# DA14531 register map
Vendor: Dialog; Series: DA14531; File version: 1.2
CPU: CM0 r1p0, little endian, MPU, FPU, 3 interrupt priority bits
Registers are 16-bit, read-write, reset 0x0 unless marked. A register's access mark holds for its fields unless they carry their own. Offsets are from the block's base; [hi:lo] are bit positions; {n}, {i} and the like mark numbered series.

## PATCH — PATCH registers
Base 0x40080000
0x00 PATCH_VALID_REG 32-bit
  [21:0] PATCH_VALID
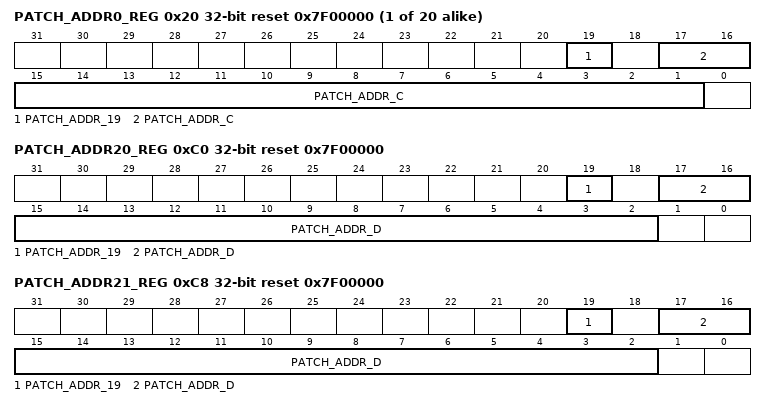
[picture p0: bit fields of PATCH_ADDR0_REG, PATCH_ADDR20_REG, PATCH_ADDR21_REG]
{0x20+8i} PATCH_ADDR{i}_REG 32-bit reset 0x7F00000 (i=0..19)
  [19] PATCH_ADDR_19, [17:1] PATCH_ADDR_C
0xC0 PATCH_ADDR20_REG 32-bit reset 0x7F00000
  [19] PATCH_ADDR_19, [17:2] PATCH_ADDR_D
0xC4 PATCH_DATA20_REG 32-bit (reset mask 0x7FFFFFFF)
  [31:0] PATCH_DATA
0xC8 PATCH_ADDR21_REG 32-bit reset 0x7F00000
  [19] PATCH_ADDR_19, [17:2] PATCH_ADDR_D
0xCC PATCH_DATA21_REG 32-bit (reset mask 0x7FFFFFFF)
  [31:0] PATCH_DATA

## QUADEC — QUADEC registers
Base 0x50000200
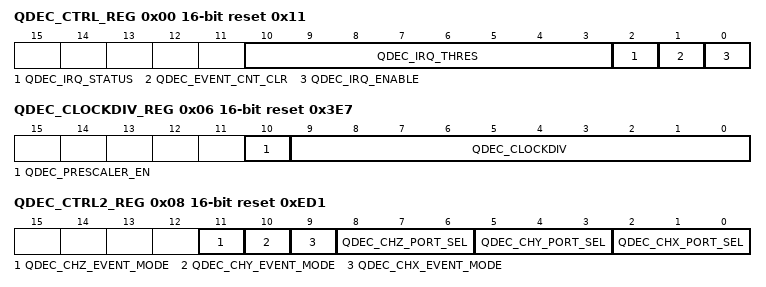
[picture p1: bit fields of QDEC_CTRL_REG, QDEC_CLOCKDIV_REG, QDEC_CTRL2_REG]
0x00 QDEC_CTRL_REG reset 0x11 — Quad Decoder control register
  [10:3] QDEC_IRQ_THRES — Defines the number of events on either counter (X or Y or Z) that need to be reached before an interrupt is generated. Events are equal to QDEC_IRQ_THRES+1.
  [2] QDEC_IRQ_STATUS — 1 = Interrupt is occured. 0 = No interrupt pending Write 1 will clear the pending interrupt
  [1] QDEC_EVENT_CNT_CLR — Writing 1 QDEC_EVENT_CNT_REG is cleared
  [0] QDEC_IRQ_ENABLE — 0 = interrupt is masked 1 = interrupt is enabled
0x02 QDEC_XCNT_REG — Counter value of the X Axis
  [15:0] QDEC_X_CNT ro — Contains a signed value of the events. Zero when channel is disabled
0x04 QDEC_YCNT_REG — Counter value of the Y Axis
  [15:0] QDEC_Y_CNT ro — Contains a signed value of the events. Zero when channel is disabled
0x06 QDEC_CLOCKDIV_REG reset 0x3E7 — Clock divider register
  [10] QDEC_PRESCALER_EN — 0 = no prescaler enabled 1 = in sleep and active mode, quadrature clock is divided by 2
  [9:0] QDEC_CLOCKDIV — Contains the number of the input clock cycles minus one, that are required to generate one logic clock cycle. Clock divider is bypassed when system runs at LP_CLK
0x08 QDEC_CTRL2_REG reset 0xED1 — Quad Decoder port selection register
  [11] QDEC_CHZ_EVENT_MODE — 0 = Normal quadrature counting 1 = Counts rising and falling edge of both ports (if both ports change at the same time, counter increases by 1)
  [10] QDEC_CHY_EVENT_MODE — 0 = Normal quadrature counting 1 = Counts rising and falling edge of both ports (if both ports change at the same time, counter increases by 1)
  [9] QDEC_CHX_EVENT_MODE — 0 = Normal quadrature counting 1 = Counts rising and falling edge of both ports (if both ports change at the same time, counter increases by 1)
  [8:6] QDEC_CHZ_PORT_SEL — Defines which GPIOs are mapped on Channel Z 0: none 1: P0[2] -> CHZ_A, P0[5] -> CHZ_B 2: P0[1] -> CHZ_A, P0[4] -> CHZ_B 3: P0[3] -> CHZ_A, P0[10] -> CHZ_B 4: P0[6] -> CHZ_A, P0[7] -> CHZ_B 5: P0[8] -> CHZ_A, P0[9] -> CHZ_B 6: P0[0] -> CHZ_A, P0[11] -> CHZ_B 7: none
  [5:3] QDEC_CHY_PORT_SEL — Defines which GPIOs are mapped on Channel Y 0: none 1: P0[2] -> CHY_A, P0[5] -> CHY_B 2: P0[1] -> CHY_A, P0[4] -> CHY_B 3: P0[3] -> CHY_A, P0[10] -> CHY_B 4: P0[6] -> CHY_A, P0[7] -> CHY_B 5: P0[8] -> CHY_A, P0[9] -> CHY_B 6: P0[0] -> CHY_A, P0[11] -> CHY_B 7: none
  [2:0] QDEC_CHX_PORT_SEL — Defines which GPIOs are mapped on Channel X 0: none 1: P0[2] -> CHX_A, P0[5] -> CHX_B 2: P0[1] -> CHX_A, P0[4] -> CHX_B 3: P0[3] -> CHX_A, P0[10] -> CHX_B 4: P0[6] -> CHX_A, P0[7] -> CHX_B 5: P0[8] -> CHX_A, P0[9] -> CHX_B 6: P0[0] -> CHX_A, P0[11] -> CHX_B 7: none
0x0A QDEC_ZCNT_REG — Counter value of the Z Axis
  [15:0] QDEC_Z_CNT ro — Contains a signed value of the events. Zero when channel is disabled
0x0C QDEC_EVENT_CNT_REG — Event counter register
  [7:0] QDEC_EVENT_CNT ro — Gives the number of events at all channels.

## RFCU — RFCU registers
Base 0x40001000
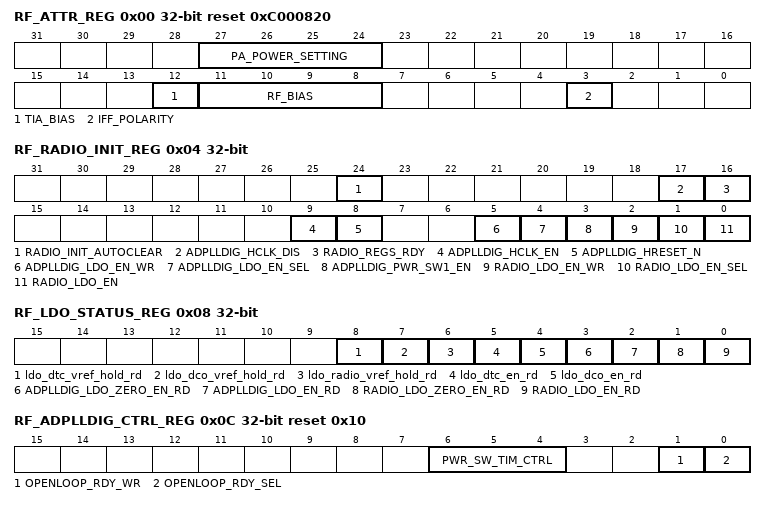
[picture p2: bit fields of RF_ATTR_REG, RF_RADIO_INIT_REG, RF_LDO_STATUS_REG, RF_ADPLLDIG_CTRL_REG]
0x00 RF_ATTR_REG 32-bit reset 0xC000820
  [27:24] PA_POWER_SETTING, [12] TIA_BIAS, [11:8] RF_BIAS, [3] IFF_POLARITY
0x04 RF_RADIO_INIT_REG 32-bit
  [24] RADIO_INIT_AUTOCLEAR, [17] ADPLLDIG_HCLK_DIS, [16] RADIO_REGS_RDY, [9] ADPLLDIG_HCLK_EN, [8] ADPLLDIG_HRESET_N, [5] ADPLLDIG_LDO_EN_WR, [4] ADPLLDIG_LDO_EN_SEL, [3] ADPLLDIG_PWR_SW1_EN, [2] RADIO_LDO_EN_WR, [1] RADIO_LDO_EN_SEL, [0] RADIO_LDO_EN
0x08 RF_LDO_STATUS_REG 32-bit
  [8] ldo_dtc_vref_hold_rd ro, [7] ldo_dco_vref_hold_rd ro, [6] ldo_radio_vref_hold_rd ro, [5] ldo_dtc_en_rd ro, [4] ldo_dco_en_rd ro, [3] ADPLLDIG_LDO_ZERO_EN_RD ro, [2] ADPLLDIG_LDO_EN_RD ro, [1] RADIO_LDO_ZERO_EN_RD ro, [0] RADIO_LDO_EN_RD ro
0x0C RF_ADPLLDIG_CTRL_REG 32-bit reset 0x10
  [6:4] PWR_SW_TIM_CTRL, [1] OPENLOOP_RDY_WR, [0] OPENLOOP_RDY_SEL
0x10 RF_AGC_EXT_LUT_REG 32-bit
  [9:0] AGC_EXT_LUT
0x14 RF_CALSTATE_REG 32-bit
  [3:0] CALSTATE ro
0x18 RF_SCAN_FEEDBACK_REG 32-bit (reset mask 0xFFFF)
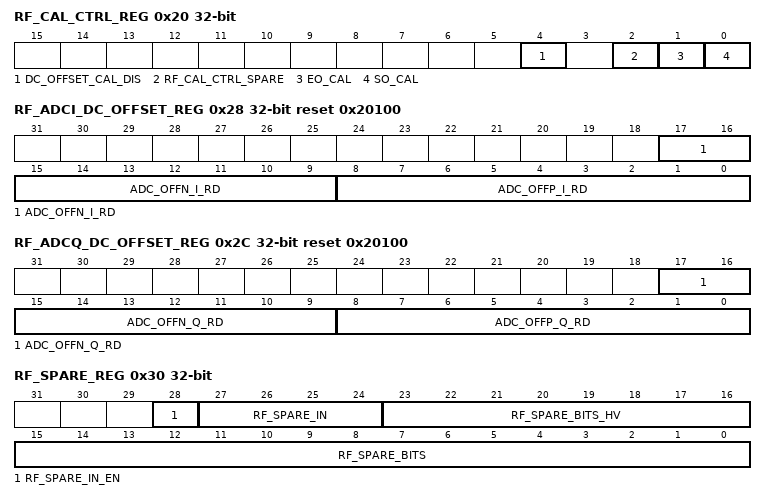
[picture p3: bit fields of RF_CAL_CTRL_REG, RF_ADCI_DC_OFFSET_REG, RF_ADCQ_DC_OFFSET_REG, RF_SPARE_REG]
0x20 RF_CAL_CTRL_REG 32-bit
  [4] DC_OFFSET_CAL_DIS, [2] RF_CAL_CTRL_SPARE, [1] EO_CAL ro, [0] SO_CAL wo
0x24 RF_IRQ_CTRL_REG 32-bit reset 0x1
  [0] EO_CAL_CLEAR wo
0x28 RF_ADCI_DC_OFFSET_REG 32-bit reset 0x20100
  [17:9] ADC_OFFN_I_RD ro, [8:0] ADC_OFFP_I_RD ro
0x2C RF_ADCQ_DC_OFFSET_REG 32-bit reset 0x20100
  [17:9] ADC_OFFN_Q_RD ro, [8:0] ADC_OFFP_Q_RD ro
0x30 RF_SPARE_REG 32-bit
  [28] RF_SPARE_IN_EN, [27:24] RF_SPARE_IN ro, [23:16] RF_SPARE_BITS_HV, [15:0] RF_SPARE_BITS
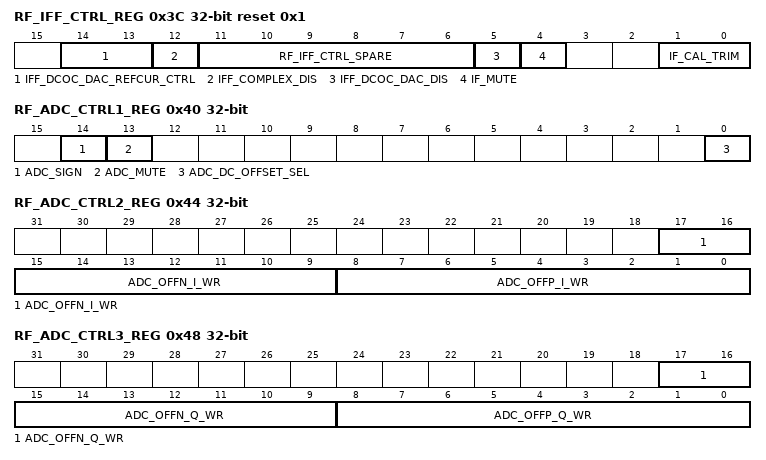
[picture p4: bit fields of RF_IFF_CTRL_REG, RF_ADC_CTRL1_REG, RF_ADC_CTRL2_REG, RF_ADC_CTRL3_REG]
0x3C RF_IFF_CTRL_REG 32-bit reset 0x1
  [14:13] IFF_DCOC_DAC_REFCUR_CTRL, [12] IFF_COMPLEX_DIS, [11:6] RF_IFF_CTRL_SPARE, [5] IFF_DCOC_DAC_DIS, [4] IF_MUTE, [1:0] IF_CAL_TRIM
0x40 RF_ADC_CTRL1_REG 32-bit
  [14] ADC_SIGN, [13] ADC_MUTE, [0] ADC_DC_OFFSET_SEL
0x44 RF_ADC_CTRL2_REG 32-bit
  [17:9] ADC_OFFN_I_WR, [8:0] ADC_OFFP_I_WR
0x48 RF_ADC_CTRL3_REG 32-bit
  [17:9] ADC_OFFN_Q_WR, [8:0] ADC_OFFP_Q_WR
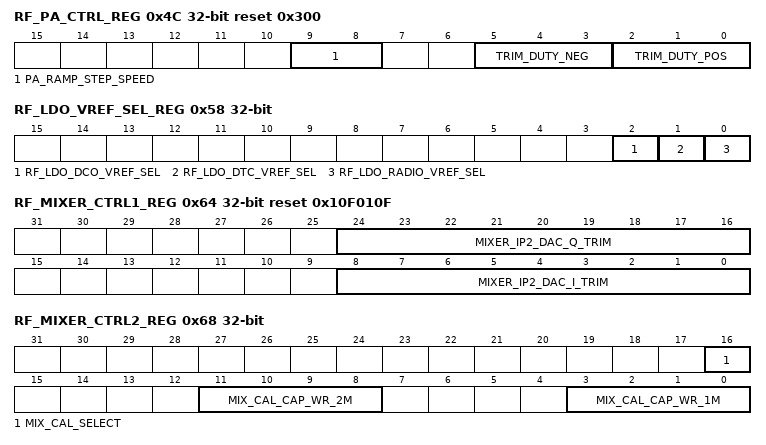
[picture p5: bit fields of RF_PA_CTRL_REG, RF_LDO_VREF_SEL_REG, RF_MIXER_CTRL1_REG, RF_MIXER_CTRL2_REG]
0x4C RF_PA_CTRL_REG 32-bit reset 0x300
  [9:8] PA_RAMP_STEP_SPEED, [5:3] TRIM_DUTY_NEG, [2:0] TRIM_DUTY_POS
0x58 RF_LDO_VREF_SEL_REG 32-bit
  [2] RF_LDO_DCO_VREF_SEL, [1] RF_LDO_DTC_VREF_SEL, [0] RF_LDO_RADIO_VREF_SEL
0x64 RF_MIXER_CTRL1_REG 32-bit reset 0x10F010F
  [24:16] MIXER_IP2_DAC_Q_TRIM, [8:0] MIXER_IP2_DAC_I_TRIM
0x68 RF_MIXER_CTRL2_REG 32-bit
  [16] MIX_CAL_SELECT, [11:8] MIX_CAL_CAP_WR_2M, [3:0] MIX_CAL_CAP_WR_1M
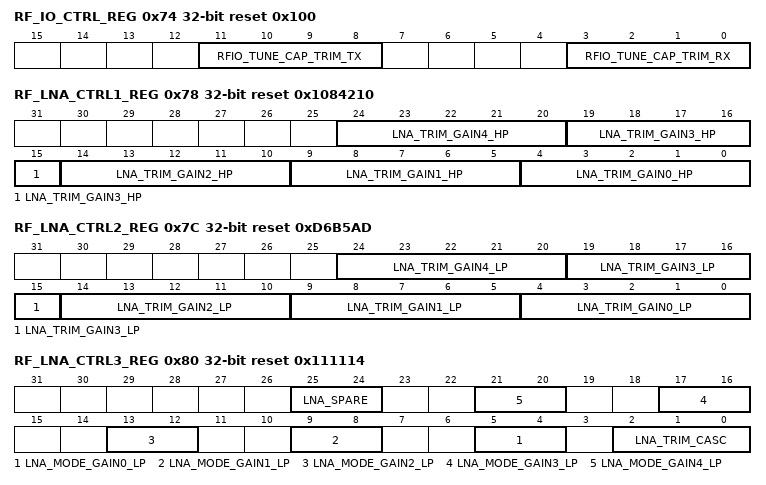
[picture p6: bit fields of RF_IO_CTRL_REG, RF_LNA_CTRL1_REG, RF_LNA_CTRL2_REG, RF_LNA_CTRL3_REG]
0x74 RF_IO_CTRL_REG 32-bit reset 0x100
  [11:8] RFIO_TUNE_CAP_TRIM_TX, [3:0] RFIO_TUNE_CAP_TRIM_RX
0x78 RF_LNA_CTRL1_REG 32-bit reset 0x1084210
  [5n+4:5n] LNA_TRIM_GAIN{n}_HP (n=0..4)
0x7C RF_LNA_CTRL2_REG 32-bit reset 0xD6B5AD
  [5n+4:5n] LNA_TRIM_GAIN{n}_LP (n=0..4)
0x80 RF_LNA_CTRL3_REG 32-bit reset 0x111114
  [25:24] LNA_SPARE, [4n+5:4n+4] LNA_MODE_GAIN{n}_LP (n=0..4), [2:0] LNA_TRIM_CASC
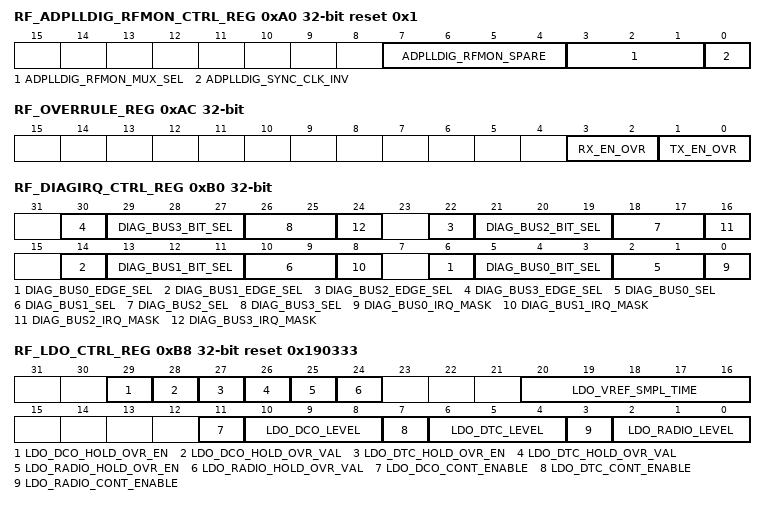
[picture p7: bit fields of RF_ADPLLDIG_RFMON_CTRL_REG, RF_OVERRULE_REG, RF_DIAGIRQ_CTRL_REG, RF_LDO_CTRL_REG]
0xA0 RF_ADPLLDIG_RFMON_CTRL_REG 32-bit reset 0x1
  [7:4] ADPLLDIG_RFMON_SPARE, [3:1] ADPLLDIG_RFMON_MUX_SEL, [0] ADPLLDIG_SYNC_CLK_INV
0xA8 RF_RFCU_CTRL_REG 32-bit reset 0x1
  [0] RF_RFCU_CLK_DIV
0xAC RF_OVERRULE_REG 32-bit
  [3:2] RX_EN_OVR, [1:0] TX_EN_OVR
0xB0 RF_DIAGIRQ_CTRL_REG 32-bit
  [8n+6] DIAG_BUS{n}_EDGE_SEL (n=0..3), [8n+5:8n+3] DIAG_BUS{n}_BIT_SEL (n=0..3), [8n+2:8n+1] DIAG_BUS{n}_SEL (n=0..3), [8n] DIAG_BUS{n}_IRQ_MASK (n=0..3)
0xB4 RF_DIAGIRQ_STAT_REG 32-bit
  [3:0] DIAGIRQ_STAT ro
0xB8 RF_LDO_CTRL_REG 32-bit reset 0x190333
  [29] LDO_DCO_HOLD_OVR_EN, [28] LDO_DCO_HOLD_OVR_VAL, [27] LDO_DTC_HOLD_OVR_EN, [26] LDO_DTC_HOLD_OVR_VAL, [25] LDO_RADIO_HOLD_OVR_EN, [24] LDO_RADIO_HOLD_OVR_VAL, [20:16] LDO_VREF_SMPL_TIME, [11] LDO_DCO_CONT_ENABLE, [10:8] LDO_DCO_LEVEL, [7] LDO_DTC_CONT_ENABLE, [6:4] LDO_DTC_LEVEL, [3] LDO_RADIO_CONT_ENABLE, [2:0] LDO_RADIO_LEVEL
